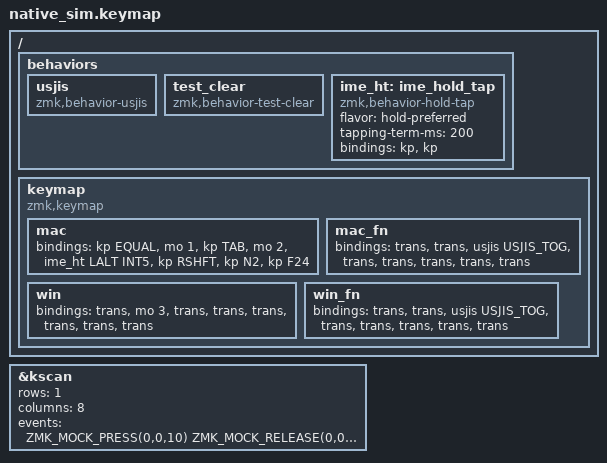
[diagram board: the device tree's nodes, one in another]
/* Generated by tests/zmk/generate.py; do not edit. */
#include <dt-bindings/zmk/keys.h>
#include <behaviors.dtsi>
#include <dt-bindings/zmk/kscan_mock.h>
#include <dt-bindings/zmk/usjis.h>

&kscan {
    rows = <1>;
    columns = <8>;
    events = <
        ZMK_MOCK_PRESS(0,0,10)
        ZMK_MOCK_RELEASE(0,0,10)
        ZMK_MOCK_PRESS(0,1,10)
        ZMK_MOCK_PRESS(0,2,10)
        ZMK_MOCK_RELEASE(0,2,10)
        ZMK_MOCK_RELEASE(0,1,10)
        ZMK_MOCK_PRESS(0,0,10)
        ZMK_MOCK_RELEASE(0,0,10)
        ZMK_MOCK_PRESS(0,3,10)
        ZMK_MOCK_PRESS(0,0,10)
        ZMK_MOCK_RELEASE(0,0,10)
        ZMK_MOCK_PRESS(0,5,10)
        ZMK_MOCK_PRESS(0,6,10)
        ZMK_MOCK_RELEASE(0,6,10)
        ZMK_MOCK_RELEASE(0,5,10)
        ZMK_MOCK_PRESS(0,4,10)
        ZMK_MOCK_PRESS(0,0,10)
        ZMK_MOCK_RELEASE(0,0,10)
        ZMK_MOCK_RELEASE(0,4,10)
        ZMK_MOCK_PRESS(0,4,10)
        ZMK_MOCK_RELEASE(0,4,10)
        ZMK_MOCK_PRESS(0,7,10)
        ZMK_MOCK_RELEASE(0,7,10)
        ZMK_MOCK_PRESS(0,1,10)
        ZMK_MOCK_PRESS(0,2,10)
        ZMK_MOCK_RELEASE(0,2,10)
        ZMK_MOCK_RELEASE(0,1,10)
        ZMK_MOCK_PRESS(0,0,10)
        ZMK_MOCK_RELEASE(0,0,10)
        ZMK_MOCK_RELEASE(0,3,10)
    >;
};

/ {
    behaviors {
        usjis: usjis {
            compatible = "zmk,behavior-usjis";
            #binding-cells = <1>;
        };
        test_clear: test_clear {
            compatible = "zmk,behavior-test-clear";
            #binding-cells = <0>;
        };
    };
};

/ {
    behaviors {
        ime_ht: ime_hold_tap {
            compatible = "zmk,behavior-hold-tap";
            #binding-cells = <2>;
            flavor = "hold-preferred";
            tapping-term-ms = <200>;
            bindings = <&kp>, <&kp>;
        };
    };

    /* The B1 Pro's layers: 0 Mac, 1 Mac Fn, 2 Win (held by the OS switch),
     * 3 Win Fn. Fn+Tab toggles the mode, which applies in Win only. */
    keymap {
        compatible = "zmk,keymap";
        mac {
            bindings = <&kp EQUAL &mo 1 &kp TAB &mo 2 &ime_ht LALT INT5 &kp RSHFT &kp N2 &kp F24>;
        };
        mac_fn {
            bindings = <&trans &trans &usjis USJIS_TOG &trans &trans &trans &trans &trans>;
        };
        win {
            bindings = <&trans &mo 3 &trans &trans &trans &trans &trans &trans>;
        };
        win_fn {
            bindings = <&trans &trans &usjis USJIS_TOG &trans &trans &trans &trans &trans>;
        };
    };
};
